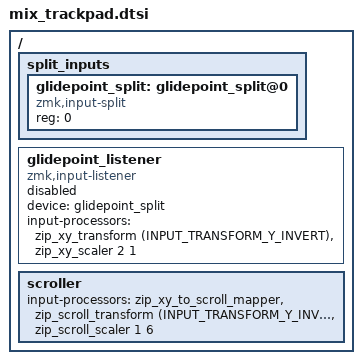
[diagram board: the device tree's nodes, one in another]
#include <dt-bindings/zmk/outputs.h>
#include <zephyr/dt-bindings/input/input-event-codes.h>
#include <input/processors.dtsi>
#include <dt-bindings/zmk/input_transform.h>
#include <dt-bindings/zmk/ext_power.h>
#include <dt-bindings/zmk/pointing.h>

#include "mix.dtsi"

/ {
    split_inputs {
        #address-cells = <1>;
        #size-cells = <0>;

        glidepoint_split: glidepoint_split@0 {
            compatible = "zmk,input-split";
            reg = <0>;
        };
    };

    glidepoint_listener: glidepoint_listener {
        compatible = "zmk,input-listener";
        status = "disabled";
        device = <&glidepoint_split>;
        input-processors = 
            <&zip_xy_transform (INPUT_TRANSFORM_Y_INVERT)>,
            <&zip_xy_scaler 2 1>;
    };

    scroller {
        //layers = <SCROLL>;
        input-processors =
            <&zip_xy_to_scroll_mapper>,
            <&zip_scroll_transform (INPUT_TRANSFORM_Y_INVERT)>,
            <&zip_scroll_scaler 1 6>;
    }; // end scroller
};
